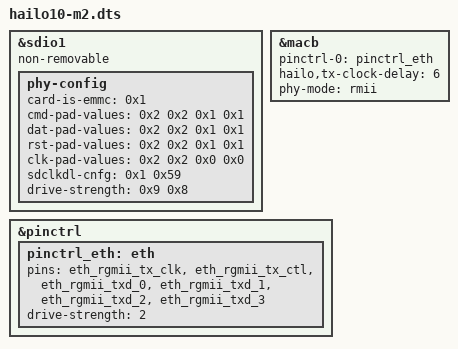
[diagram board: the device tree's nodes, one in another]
// SPDX-License-Identifier: GPL-2.0
/*
 * dts file for Hailo Hailo10-m.2 SoC
 *
 * Copyright (c) 2019-2024 Hailo Technologies Ltd. All rights reserved.
 */
#include "hailo10-base.dtsi"
#include "hailo15_ddr_configuration.dtsi"
#include "hailo15_ddr_MT53E2G32D4DE-046_regconfig_8GB.dtsi"
//#include "hailo15_ddr_MT53E1G32D2FW-046_regconfig_ca_odtb_pu_4GB.dtsi"

&sdio1 {
    non-removable;
    phy-config {
            card-is-emmc = <0x1>;
            cmd-pad-values = <0x2 0x2 0x1 0x1>; // txslew_ctrl_n, txslew_ctrl_p, weakpull_enable, rxsel
            dat-pad-values = <0x2 0x2 0x1 0x1>; // txslew_ctrl_n, txslew_ctrl_p, weakpull_enable, rxsel
            rst-pad-values = <0x2 0x2 0x1 0x1>; // txslew_ctrl_n, txslew_ctrl_p, weakpull_enable, rxsel
            clk-pad-values = <0x2 0x2 0x0 0x0>; // txslew_ctrl_n, txslew_ctrl_p, weakpull_enable, rxsel
            sdclkdl-cnfg = <0x1 0x59>; //extdly_en, cckdl_dc
            drive-strength = <0x9 0x8>; //pad_sp, pad_sn
            u-boot,dm-spl;
    };
};

&macb {
    status = "okay";
    pinctrl-names = "default";
    pinctrl-0 = <&pinctrl_eth>;
    hailo,tx-clock-delay = <6>;
    phy-mode = "rmii";
};

&pinctrl {
    pinctrl_eth: eth {
        pins = "eth_rgmii_tx_clk",
               "eth_rgmii_tx_ctl",
               "eth_rgmii_txd_0",
               "eth_rgmii_txd_1",
               "eth_rgmii_txd_2",
               "eth_rgmii_txd_3";
        drive-strength = <2>;
    };
};
